# STM32F103 register map
File version: 1.1
CPU: CM3 r1p1, little endian, no MPU, no FPU, 4 interrupt priority bits
Registers are 32-bit, read-write, reset 0x0 unless marked. A register's access mark holds for its fields unless they carry their own. Offsets are from the block's base; [hi:lo] are bit positions; {n}, {i} and the like mark numbered series; 'fields as' and 'values as' point back to an identical list.

## IWDG — Independent watchdog
Base 0x40003000
0x00 KR 16-bit wo — Key register (IWDG_KR)
  [15:0] KEY — Key value
    0x5555=Unlock (Enable access to PR, RLR and WINR registers); 0xAAAA=Feed watchdog with RLR register value; 0xCCCC=Start the watchdog
0x04 PR 16-bit — Prescaler register (IWDG_PR)
  [2:0] PR — Prescaler divider
    0=DivideBy4 (Divider /4); 1=DivideBy8 (Divider /8); 2=DivideBy16 (Divider /16); 3=DivideBy32 (Divider /32); 4=DivideBy64 (Divider /64); 5=DivideBy128 (Divider /128); other=DivideBy256 (Divider /256)
0x08 RLR 16-bit reset 0xFFF — Reload register (IWDG_RLR)
  [11:0] RL — Watchdog counter reload value
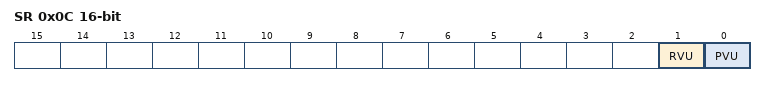
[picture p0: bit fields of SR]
0x0C SR 16-bit ro — Status register (IWDG_SR)
  [1] RVU — Watchdog counter reload value update
  [0] PVU — Watchdog prescaler value update

## WWDG — Window watchdog
Base 0x40002C00
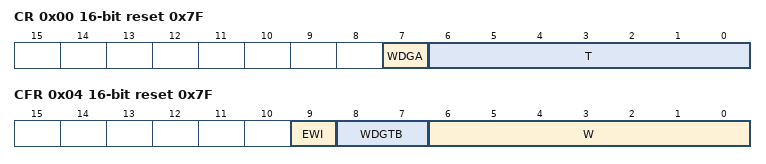
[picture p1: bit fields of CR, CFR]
0x00 CR 16-bit reset 0x7F — Control register (WWDG_CR)
  [7] WDGA — Activation bit
    0=Disabled (Watchdog disabled); 1=Enabled (Watchdog enabled)
  [6:0] T — 7-bit counter (MSB to LSB)
0x04 CFR 16-bit reset 0x7F — Configuration register (WWDG_CFR)
  [9] EWI — Early Wakeup Interrupt
    on write: 1=Enable (interrupt occurs whenever the counter reaches the value 0x40)
  [8:7] WDGTB — Timer Base
    0=Div1 (Counter clock (PCLK1 div 4096) div 1); 1=Div2 (Counter clock (PCLK1 div 4096) div 2); 2=Div4 (Counter clock (PCLK1 div 4096) div 4); 3=Div8 (Counter clock (PCLK1 div 4096) div 8)
  [6:0] W — 7-bit window value
0x08 SR 16-bit — Status register (WWDG_SR)
  [0] EWIF write-0-clears — Early Wakeup Interrupt
    on read: 0=Finished (The EWI Interrupt Service Routine has been serviced); 1=Pending (The EWI Interrupt Service Routine has been triggered) | on write: 0=Finished (The EWI Interrupt Service Routine has been serviced)

## TIM6 — Basic timer
Base 0x40001000
Same registers: TIM7 0x40001400
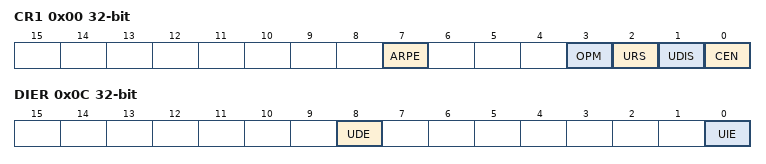
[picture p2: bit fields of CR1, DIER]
0x00 CR1 — control register 1
  [7] ARPE — Auto-reload preload enable
    0=Disabled (TIMx_APRR register is not buffered); 1=Enabled (TIMx_APRR register is buffered)
  [3] OPM — One-pulse mode
    0=Disabled (Counter is not stopped at update event); 1=Enabled (Counter stops counting at the next update event (clearing the CEN bit))
  [2] URS — Update request source
    0=AnyEvent (Any of counter overflow/underflow, setting UG, or update through slave mode, generates an update interrupt or DMA request); 1=CounterOnly (Only counter overflow/underflow generates an update interrupt or DMA request)
  [1] UDIS — Update disable
    0=Enabled (Update event enabled); 1=Disabled (Update event disabled)
  [0] CEN — Counter enable
    0=Disabled (Counter disabled); 1=Enabled (Counter enabled)
0x04 CR2 — control register 2
  [6:4] MMS — Master mode selection
    0=Reset (Use UG bit from TIMx_EGR register); 1=Enable (Use CNT bit from TIMx_CEN register); 2=Update (Use the update event)
0x0C DIER — DMA/Interrupt enable register
  [8] UDE — Update DMA request enable
    0=Disabled (Update DMA request disabled); 1=Enabled (Update DMA request enabled)
  [0] UIE — Update interrupt enable
    0=Disabled (Update interrupt disabled); 1=Enabled (Update interrupt enabled)
0x10 SR — status register
  [0] UIF write-0-clears — Update interrupt flag
    on read: 0=NoUpdateOccurred; 1=UpdatePending (Update interrupt pending) | on write: 0=Clear flag
0x14 EGR wo — event generation register
  [0] UG — Update generation
    1=Update (Re-initializes the timer counter and generates an update of the registers.)
0x24 CNT — counter
  [15:0] CNT — Low counter value
0x28 PSC — prescaler
  [15:0] PSC — Prescaler value
0x2C ARR — auto-reload register
  [15:0] ARR — Low Auto-reload value

## DAC — Digital to analog converter
Base 0x40007400
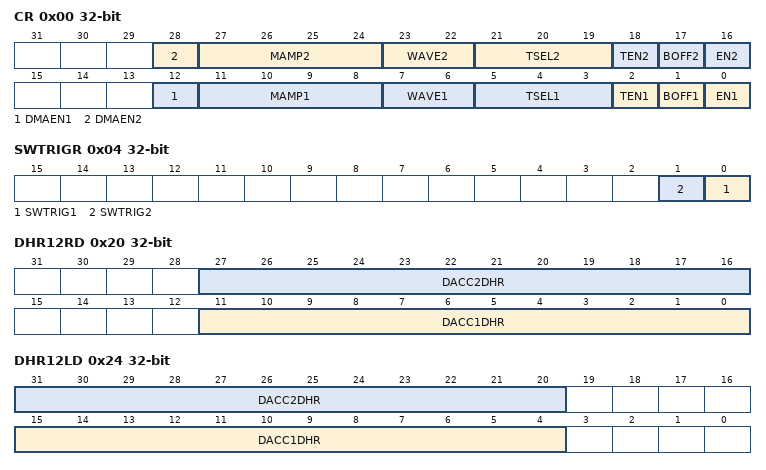
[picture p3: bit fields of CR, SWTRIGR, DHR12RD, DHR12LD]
0x00 CR — Control register (DAC_CR)
  [21:19] TSEL2 — DAC channel2 trigger selection
    0=Tim6Trgo (Timer 6 TRGO event); 1=Tim8Trgo (Timer 8 TRGO event); 2=Tim7Trgo (Timer 7 TRGO event); 3=Tim5Trgo (Timer 5 TRGO event); 4=Tim2Trgo (Timer 2 TRGO event); 5=Tim4Trgo (Timer 4 TRGO event); 6=Exti9 (EXTI line 9); 7=Swtrig (Software trigger)
  [16n-4] DMAEN{n} (n=1..2) — DAC channel{n} DMA enable
    0=Disabled (DAC channel X DMA mode disabled); 1=Enabled (DAC channel X DMA mode enabled)
  [16n-5:16n-8] MAMP{n} (n=1..2) — DAC channel{n} mask/amplitude selector
    0=Amp1 (Unmask bit0 of LFSR/ triangle amplitude equal to 1); 1=Amp3 (Unmask bits[1:0] of LFSR/ triangle amplitude equal to 3); 2=Amp7 (Unmask bits[2:0] of LFSR/ triangle amplitude equal to 7); 3=Amp15 (Unmask bits[3:0] of LFSR/ triangle amplitude equal to 15); 4=Amp31 (Unmask bits[4:0] of LFSR/ triangle amplitude equal to 31); 5=Amp63 (Unmask bits[5:0] of LFSR/ triangle amplitude equal 63); 6=Amp127 (Unmask bits[6:0] of LFSR/ triangle amplitude equal to 127); 7=Amp255 (Unmask bits[7:0] of LFSR/ triangle amplitude equal to 255); 8=Amp511 (Unmask bits[8:0] of LFSR/ triangle amplitude equal to 511); 9=Amp1023 (Unmask bits[9:0] of LFSR/ triangle amplitude equal to 1023); 10=Amp2047 (Unmask bits[10:0] of LFSR/ triangle amplitude equal to 2047); other=Amp4095 (Unmask bits[11:0] of LFSR/ triangle amplitude equal to 4095)
  [16n-9:16n-10] WAVE{n} (n=1..2) — DAC channel{n} noise/triangle wave generation enable
    0=Disabled (Wave generation disabled); 1=Noise wave generation enabled; other=Triangle wave generation enabled
  [5:3] TSEL1 — DAC channel1 trigger selection
    values as TSEL2
  [16n-14] TEN{n} (n=1..2) — DAC channel{n} trigger enable
    0=Disabled (DAC channel X trigger disabled); 1=Enabled (DAC channel X trigger enabled)
  [16n-15] BOFF{n} (n=1..2) — DAC channel{n} output buffer disable
    0=Enabled (DAC channel X output buffer enabled); 1=Disabled (DAC channel X output buffer disabled)
  [16n-16] EN{n} (n=1..2) — DAC channel{n} enable
    0=Disabled (DAC channel X disabled); 1=Enabled (DAC channel X enabled)
0x04 SWTRIGR wo — DAC software trigger register (DAC_SWTRIGR)
  [n-1] SWTRIG{n} (n=1..2) — DAC channel{n} software trigger
    0=Disabled (DAC channel X software trigger disabled); 1=Enabled (DAC channel X software trigger enabled)
0x08 DHR12R{i} (i=1..2; step 0xC) — channel{i} 12-bit right-aligned data holding register
  [11:0] DACCDHR — DAC channel1 12-bit right-aligned data
{0x0+0xC*i} DHR12L{i} (i=1..2) — channel{i} 12-bit left aligned data holding register
  [15:4] DACCDHR — DAC channel1 12-bit left-aligned data
{0x4+0xC*i} DHR8R{i} (i=1..2) — channel{i} 8-bit right aligned data holding register
  [7:0] DACCDHR — DAC channel1 8-bit right-aligned data
0x20 DHR12RD — Dual DAC 12-bit right-aligned data holding register (DAC_DHR12RD), Bits 31:28 Reserved, Bits 15:12 Reserved
  [16n-5:16n-16] DACC{n}DHR (n=1..2) — DAC channel{n} 12-bit right-aligned data
0x24 DHR12LD — DUAL DAC 12-bit left aligned data holding register (DAC_DHR12LD), Bits 19:16 Reserved, Bits 3:0 Reserved
  [16n-1:16n-12] DACC{n}DHR (n=1..2) — DAC channel{n} 12-bit left-aligned data
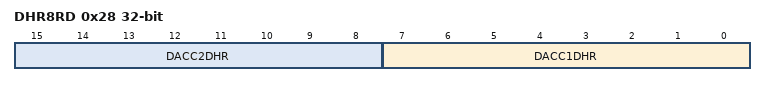
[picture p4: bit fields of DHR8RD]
0x28 DHR8RD — DUAL DAC 8-bit right aligned data holding register (DAC_DHR8RD), Bits 31:16 Reserved
  [8n-1:8n-8] DACC{n}DHR (n=1..2) — DAC channel{n} 8-bit right-aligned data
{0x28+4i} DOR{i} (i=1..2) ro — channel{i} data output register
  [11:0] DACCDOR — DAC channel1 data output
